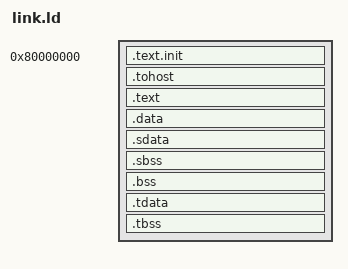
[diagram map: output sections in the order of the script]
/*
Copyright (c) 2012-2015, The Regents of the University of California (Regents).
All Rights Reserved.

Redistribution and use in source and binary forms, with or without
modification, are permitted provided that the following conditions are met:
1. Redistributions of source code must retain the above copyright
   notice, this list of conditions and the following disclaimer.
2. Redistributions in binary form must reproduce the above copyright
   notice, this list of conditions and the following disclaimer in the
   documentation and/or other materials provided with the distribution.
3. Neither the name of the Regents nor the
   names of its contributors may be used to endorse or promote products
   derived from this software without specific prior written permission.

IN NO EVENT SHALL REGENTS BE LIABLE TO ANY PARTY FOR DIRECT, INDIRECT,
SPECIAL, INCIDENTAL, OR CONSEQUENTIAL DAMAGES, INCLUDING LOST PROFITS, ARISING
OUT OF THE USE OF THIS SOFTWARE AND ITS DOCUMENTATION, EVEN IF REGENTS HAS
BEEN ADVISED OF THE POSSIBILITY OF SUCH DAMAGE.

REGENTS SPECIFICALLY DISCLAIMS ANY WARRANTIES, INCLUDING, BUT NOT LIMITED TO,
THE IMPLIED WARRANTIES OF MERCHANTABILITY AND FITNESS FOR A PARTICULAR
PURPOSE. THE SOFTWARE AND ACCOMPANYING DOCUMENTATION, IF ANY, PROVIDED
HEREUNDER IS PROVIDED "AS IS". REGENTS HAS NO OBLIGATION TO PROVIDE
MAINTENANCE, SUPPORT, UPDATES, ENHANCEMENTS, OR MODIFICATIONS.

From https://github.com/riscv-software-src/riscv-tests/tree/master/benchmarks/common
*/

/*======================================================================*/
/* Proxy kernel linker script                                           */
/*======================================================================*/
/* This is the linker script used when building the proxy kernel. */

/*----------------------------------------------------------------------*/
/* Setup                                                                */
/*----------------------------------------------------------------------*/

/* The OUTPUT_ARCH command specifies the machine architecture where the
   argument is one of the names used in the BFD library. More
   specifically one of the entires in bfd/cpu-mips.c */

OUTPUT_ARCH( "riscv" )
ENTRY(_start)

/*----------------------------------------------------------------------*/
/* Sections                                                             */
/*----------------------------------------------------------------------*/

SECTIONS
{

  /* text: test code section */
  . = 0x80000000;
  .text.init : { *(.text.init) }

  . = ALIGN(0x1000);
  .tohost : { *(.tohost) }

  .text : { *(.text) }

  /* data segment */
  .data : { *(.data) }

  .sdata : {
    __global_pointer$ = . + 0x800;
    *(.srodata.cst16) *(.srodata.cst8) *(.srodata.cst4) *(.srodata.cst2) *(.srodata*)
    *(.sdata .sdata.* .gnu.linkonce.s.*)
  }

  /* bss segment */
  .sbss : {
    *(.sbss .sbss.* .gnu.linkonce.sb.*)
    *(.scommon)
  }
  .bss : { *(.bss) }


  /* thread-local data segment */
  .tdata :
  {
    _tdata_begin = .;
    *(.tdata)
    _tdata_end = .;
  }
  .tbss :
  {
    *(.tbss)
    _tbss_end = .;
  }

  /* End of uninitalized data segement */
  _end = .;
  end = .;
}

